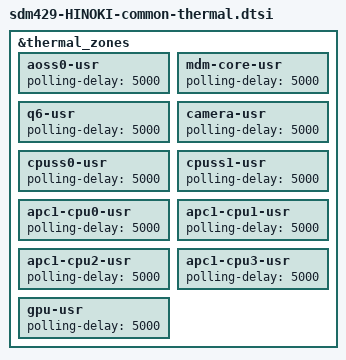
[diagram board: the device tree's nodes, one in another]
/*
 * This software is contributed or developed by KYOCERA Corporation.
 * (C) 2019 KYOCERA Corporation
 *
 * This program is free software; you can redistribute it and/or modify
 * it under the terms of the GNU General Public License version 2 and
 * only version 2 as published by the Free Software Foundation.
 *
 * This program is distributed in the hope that it will be useful,
 * but WITHOUT ANY WARRANTY; without even the implied warranty of
 * MERCHANTABILITY or FITNESS FOR A PARTICULAR PURPOSE.  See the
 * GNU General Public License for more details.
 */

&thermal_zones {
	aoss0-usr {
		polling-delay = <5000>;
	};

	mdm-core-usr {
		polling-delay = <5000>;
	};

	q6-usr {
		polling-delay = <5000>;
	};

	camera-usr {
		polling-delay = <5000>;
	};

	cpuss0-usr {
		polling-delay = <5000>;
	};

	cpuss1-usr {
		polling-delay = <5000>;
	};

	apc1-cpu0-usr {
		polling-delay = <5000>;
	};

	apc1-cpu1-usr {
		polling-delay = <5000>;
	};

	apc1-cpu2-usr {
		polling-delay = <5000>;
	};

	apc1-cpu3-usr {
		polling-delay = <5000>;
	};

	gpu-usr {
		polling-delay = <5000>;
	};

};
